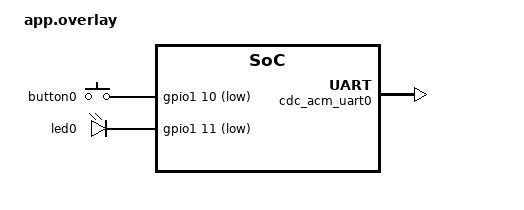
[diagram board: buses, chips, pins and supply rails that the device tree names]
/* Step 4.2 - choose CDC ACM for mcumgr */
/ {
	chosen {
		zephyr,uart-mcumgr = &cdc_acm_uart0;
	};
};

/* Step 4.1 - Configure CDC ACM */
&zephyr_udc0 {
	cdc_acm_uart0: cdc_acm_uart0 {
		compatible = "zephyr,cdc-acm-uart";
	};
};

&button0 {
	gpios = <&gpio1 10 GPIO_ACTIVE_LOW>;
};

&led0 {
	gpios = <&gpio1 11 GPIO_ACTIVE_LOW>;
};
